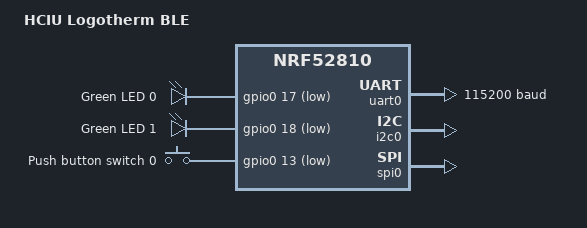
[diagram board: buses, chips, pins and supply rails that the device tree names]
/*
 * HCIU Logotherm BLE board - based on nRF52810 SoC
 * SPDX-License-Identifier: Apache-2.0
 */

/dts-v1/;
#include <nordic/nrf52810_qfaa.dtsi>
#include "hciu_logotherm_ble-pinctrl.dtsi"
#include <zephyr/dt-bindings/input/input-event-codes.h>

/ {
	model = "HCIU Logotherm BLE";
	compatible = "logotronic,hciu-logotherm-ble";

	chosen {
		zephyr,console = &uart0;
		zephyr,shell-uart = &uart0;
		zephyr,uart-mcumgr = &uart0;
		zephyr,bt-mon-uart = &uart0;
		zephyr,bt-c2h-uart = &uart0;
		zephyr,sram = &sram0;
		zephyr,flash = &flash0;
		zephyr,code-partition = &slot0_partition;
	};

	leds {
		compatible = "gpio-leds";
		led0: led_0 {
			gpios = <&gpio0 17 GPIO_ACTIVE_LOW>;
			label = "Green LED 0";
		};
		led1: led_1 {
			gpios = <&gpio0 18 GPIO_ACTIVE_LOW>;
			label = "Green LED 1";
		};
	};

	buttons {
		compatible = "gpio-keys";
		button0: button_0 {
			label = "Push button switch 0";
			gpios = <&gpio0 13 (GPIO_PULL_UP | GPIO_ACTIVE_LOW)>;
			zephyr,code = <INPUT_KEY_0>;
		};
	};

	aliases {
		led0 = &led0;
		led1 = &led1;
		sw0 = &button0;
		watchdog0 = &wdt0;
	};
};

&reg {
	regulator-initial-mode = <NRF5X_REG_MODE_DCDC>;
};

&uicr {
	gpio-as-nreset;
};

&gpiote {
	status = "okay";
};

&gpio0 {
	status = "okay";
};

&uart0 {
	compatible = "nordic,nrf-uarte";
	status = "okay";
	current-speed = <115200>;
	pinctrl-0 = <&uart0_default>;
	pinctrl-1 = <&uart0_sleep>;
	pinctrl-names = "default", "sleep";
};

&i2c0 {
	compatible = "nordic,nrf-twi";
	status = "okay";
	pinctrl-0 = <&i2c0_default>;
	pinctrl-1 = <&i2c0_sleep>;
	pinctrl-names = "default", "sleep";
};

&spi0 {
	compatible = "nordic,nrf-spi";
	status = "okay";
	pinctrl-0 = <&spi0_default>;
	pinctrl-1 = <&spi0_sleep>;
	pinctrl-names = "default", "sleep";
};

/* Flash layout — total: 192 KB (0x00000000 – 0x00030000)
 *
 * +------------------+------------+--------+----------+
 * | Partition        | Start      | Size   | KB       |
 * +------------------+------------+--------+----------+
 * | mcuboot          | 0x00000000 | 0xc000 |  48 KB   |
 * | image-0 (slot0)  | 0x0000C000 | 0xd000 |  52 KB   |
 * | image-1 (slot1)  | 0x00019000 | 0xe000 |  56 KB   |
 * | storage          | 0x00027000 | 0x9000 |  36 KB   |
 * +------------------+------------+--------+----------+
 *
 * Note: slot1 starts at partition@1a000 (0x1a000), not 0x19000 —
 * there is a 4 KB gap between slot0 end and slot1 start.
 */
&flash0 {
	partitions {
		compatible = "fixed-partitions";
		#address-cells = <1>;
		#size-cells = <1>;

		/* MCUboot bootloader: 48 KB (0x0000_0000 – 0x0000_BFFF) */
		boot_partition: partition@0 {
			label = "mcuboot";
			reg = <0x00000000 0xc000>;
		};
		/* Primary application slot: 52 KB (0x0000_C000 – 0x0001_8FFF) */
		slot0_partition: partition@c000 {
			label = "image-0";
			reg = <0x0000C000 0xe000>;
		};
		/* Secondary application slot (OTA): 56 KB (0x0001_A000 – 0x0002_7FFF) */
		slot1_partition: partition@1a000 {
			label = "image-1";
			reg = <0x0001a000 0xe000>;
		};
		/* Persistent storage (settings/NVS): 32 KB (0x0002_8000 – 0x0002_FFFF) */
		storage_partition: partition@28000 {
			label = "storage";
			reg = <0x00028000 0x00008000>;
		};
	};
};
